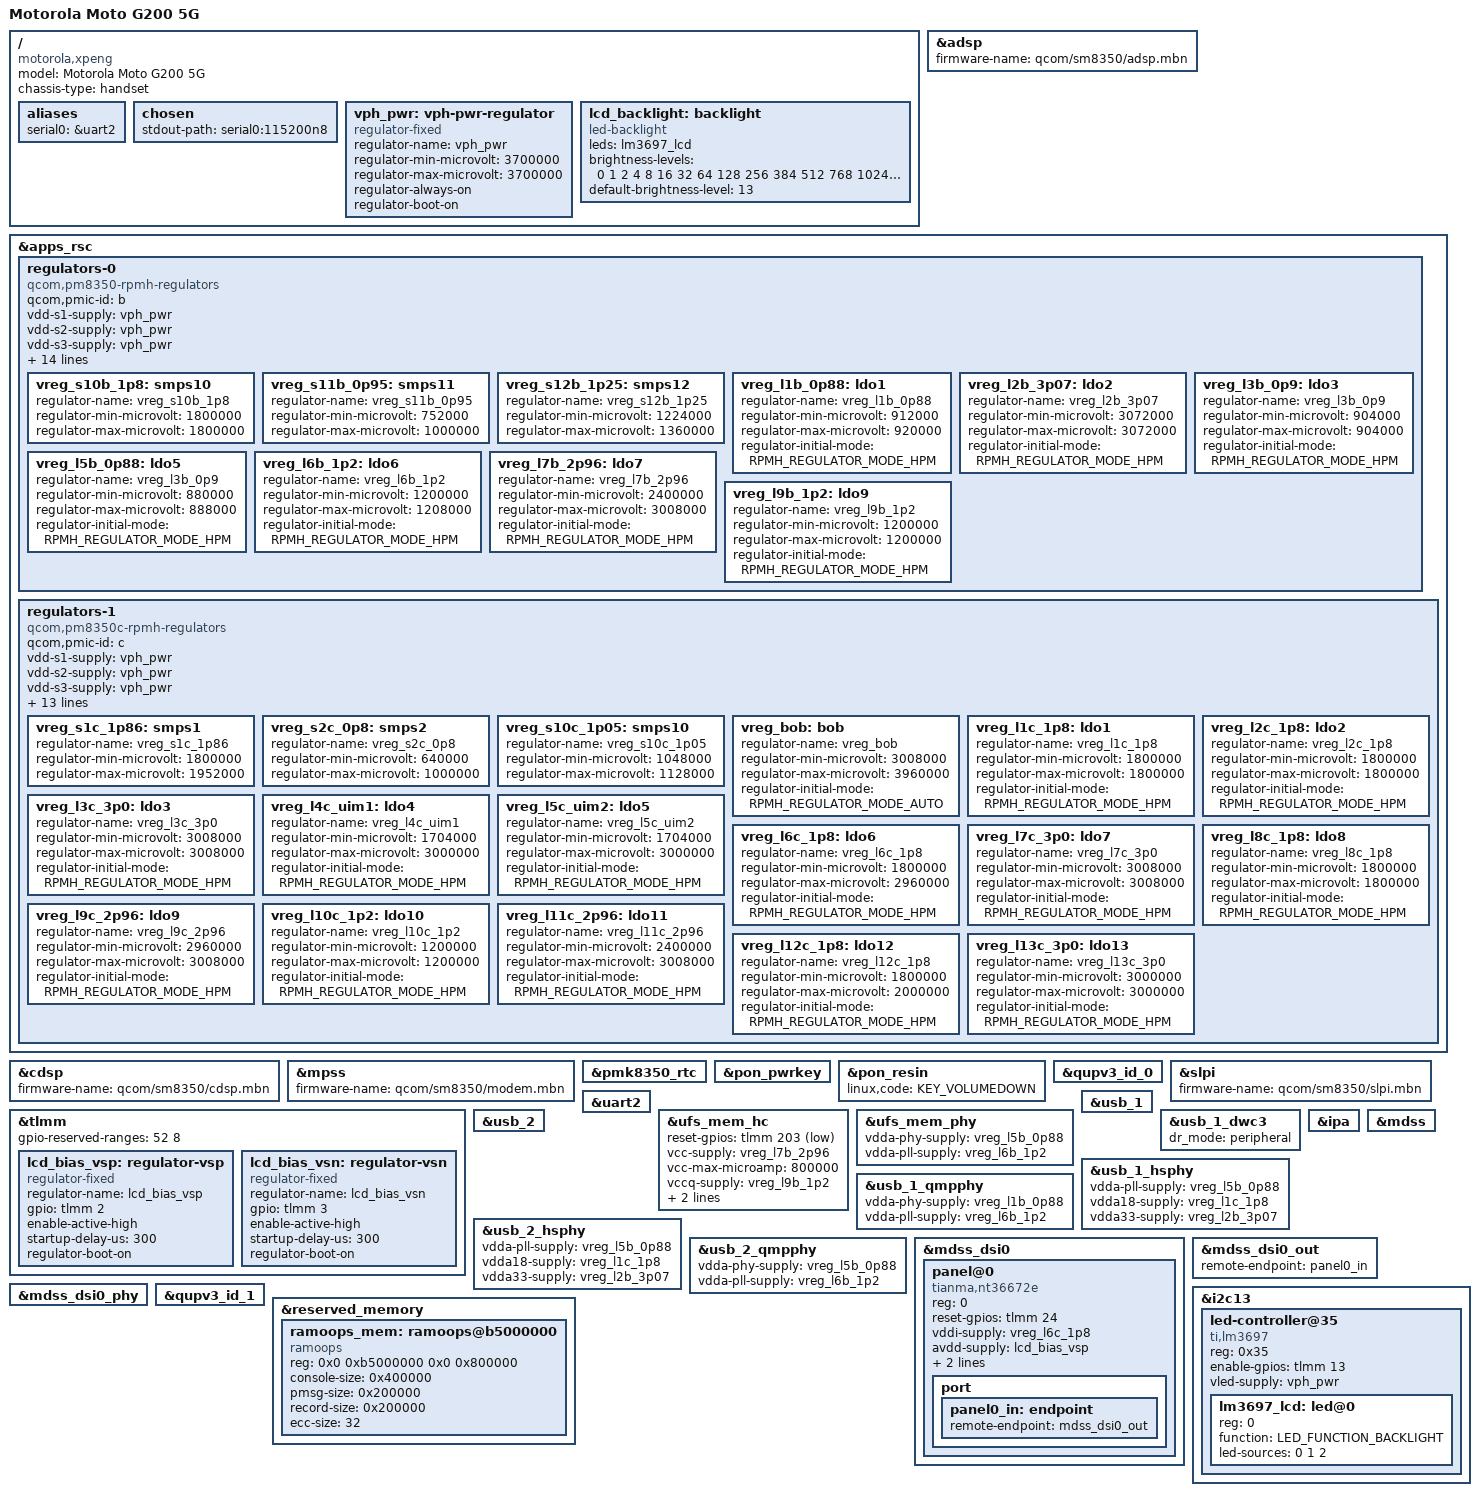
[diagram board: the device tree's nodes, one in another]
// SPDX-License-Identifier: BSD-3-Clause

/dts-v1/;

#include <dt-bindings/regulator/qcom,rpmh-regulator.h>
#include <dt-bindings/leds/common.h>
#include "sm8350.dtsi"
#include "pm8350.dtsi"
#include "pm8350b.dtsi"
#include "pm8350c.dtsi"
#include "pmk8350.dtsi"
#include "pmr735a.dtsi"
#include "pmr735b.dtsi"

/ {
	model = "Motorola Moto G200 5G";
	compatible = "motorola,xpeng", "qcom,sm8350";
	chassis-type = "handset";

	aliases {
		serial0 = &uart2;
	};

	chosen {
		stdout-path = "serial0:115200n8";
	};

	vph_pwr: vph-pwr-regulator {
		compatible = "regulator-fixed";
		regulator-name = "vph_pwr";
		regulator-min-microvolt = <3700000>;
		regulator-max-microvolt = <3700000>;

		regulator-always-on;
		regulator-boot-on;
	};
};

&adsp {
	status = "okay";
	firmware-name = "qcom/sm8350/adsp.mbn";
};

&apps_rsc {
	regulators-0 {
		compatible = "qcom,pm8350-rpmh-regulators";
		qcom,pmic-id = "b";

		vdd-s1-supply = <&vph_pwr>;
		vdd-s2-supply = <&vph_pwr>;
		vdd-s3-supply = <&vph_pwr>;
		vdd-s4-supply = <&vph_pwr>;
		vdd-s5-supply = <&vph_pwr>;
		vdd-s6-supply = <&vph_pwr>;
		vdd-s7-supply = <&vph_pwr>;
		vdd-s8-supply = <&vph_pwr>;
		vdd-s9-supply = <&vph_pwr>;
		vdd-s10-supply = <&vph_pwr>;
		vdd-s11-supply = <&vph_pwr>;
		vdd-s12-supply = <&vph_pwr>;

		vdd-l1-l4-supply = <&vreg_s11b_0p95>;
		vdd-l2-l7-supply = <&vreg_bob>;
		vdd-l3-l5-supply = <&vreg_bob>;
		vdd-l6-l9-l10-supply = <&vreg_s11b_0p95>;
		vdd-l8-supply = <&vreg_s2c_0p8>;

		vreg_s10b_1p8: smps10 {
			regulator-name = "vreg_s10b_1p8";
			regulator-min-microvolt = <1800000>;
			regulator-max-microvolt = <1800000>;
		};

		vreg_s11b_0p95: smps11 {
			regulator-name = "vreg_s11b_0p95";
			regulator-min-microvolt = <752000>;
			regulator-max-microvolt = <1000000>;
		};

		vreg_s12b_1p25: smps12 {
			regulator-name = "vreg_s12b_1p25";
			regulator-min-microvolt = <1224000>;
			regulator-max-microvolt = <1360000>;
		};

		vreg_l1b_0p88: ldo1 {
			regulator-name = "vreg_l1b_0p88";
			regulator-min-microvolt = <912000>;
			regulator-max-microvolt = <920000>;
			regulator-initial-mode = <RPMH_REGULATOR_MODE_HPM>;
		};

		vreg_l2b_3p07: ldo2 {
			regulator-name = "vreg_l2b_3p07";
			regulator-min-microvolt = <3072000>;
			regulator-max-microvolt = <3072000>;
			regulator-initial-mode = <RPMH_REGULATOR_MODE_HPM>;
		};

		vreg_l3b_0p9: ldo3 {
			regulator-name = "vreg_l3b_0p9";
			regulator-min-microvolt = <904000>;
			regulator-max-microvolt = <904000>;
			regulator-initial-mode = <RPMH_REGULATOR_MODE_HPM>;
		};

		vreg_l5b_0p88: ldo5 {
			regulator-name = "vreg_l3b_0p9";
			regulator-min-microvolt = <880000>;
			regulator-max-microvolt = <888000>;
			regulator-initial-mode = <RPMH_REGULATOR_MODE_HPM>;
		};

		vreg_l6b_1p2: ldo6 {
			regulator-name = "vreg_l6b_1p2";
			regulator-min-microvolt = <1200000>;
			regulator-max-microvolt = <1208000>;
			regulator-initial-mode = <RPMH_REGULATOR_MODE_HPM>;
		};

		vreg_l7b_2p96: ldo7 {
			regulator-name = "vreg_l7b_2p96";
			regulator-min-microvolt = <2400000>;
			regulator-max-microvolt = <3008000>;
			regulator-initial-mode = <RPMH_REGULATOR_MODE_HPM>;
		};

		vreg_l9b_1p2: ldo9 {
			regulator-name = "vreg_l9b_1p2";
			regulator-min-microvolt = <1200000>;
			regulator-max-microvolt = <1200000>;
			regulator-initial-mode = <RPMH_REGULATOR_MODE_HPM>;
		};
	};

	regulators-1 {
		compatible = "qcom,pm8350c-rpmh-regulators";
		qcom,pmic-id = "c";

		vdd-s1-supply = <&vph_pwr>;
		vdd-s2-supply = <&vph_pwr>;
		vdd-s3-supply = <&vph_pwr>;
		vdd-s4-supply = <&vph_pwr>;
		vdd-s5-supply = <&vph_pwr>;
		vdd-s6-supply = <&vph_pwr>;
		vdd-s7-supply = <&vph_pwr>;
		vdd-s8-supply = <&vph_pwr>;
		vdd-s9-supply = <&vph_pwr>;
		vdd-s10-supply = <&vph_pwr>;

		vdd-l1-l12-supply = <&vreg_s1c_1p86>;
		vdd-l2-l8-supply = <&vreg_s1c_1p86>;
		vdd-l3-l4-l5-l7-l13-supply = <&vreg_bob>;
		vdd-l6-l9-l11-supply = <&vreg_bob>;
		vdd-l10-supply = <&vreg_s12b_1p25>;

		vdd-bob-supply = <&vph_pwr>;

		vreg_s1c_1p86: smps1 {
			regulator-name = "vreg_s1c_1p86";
			regulator-min-microvolt = <1800000>;
			regulator-max-microvolt = <1952000>;
		};

		vreg_s2c_0p8: smps2 {
			regulator-name = "vreg_s2c_0p8";
			regulator-min-microvolt = <640000>;
			regulator-max-microvolt = <1000000>;
		};

		vreg_s10c_1p05: smps10 {
			regulator-name = "vreg_s10c_1p05";
			regulator-min-microvolt = <1048000>;
			regulator-max-microvolt = <1128000>;
		};

		vreg_bob: bob {
			regulator-name = "vreg_bob";
			regulator-min-microvolt = <3008000>;
			regulator-max-microvolt = <3960000>;
			regulator-initial-mode = <RPMH_REGULATOR_MODE_AUTO>;
		};

		vreg_l1c_1p8: ldo1 {
			regulator-name = "vreg_l1c_1p8";
			regulator-min-microvolt = <1800000>;
			regulator-max-microvolt = <1800000>;
			regulator-initial-mode = <RPMH_REGULATOR_MODE_HPM>;
		};

		vreg_l2c_1p8: ldo2 {
			regulator-name = "vreg_l2c_1p8";
			regulator-min-microvolt = <1800000>;
			regulator-max-microvolt = <1800000>;
			regulator-initial-mode = <RPMH_REGULATOR_MODE_HPM>;
		};

		vreg_l3c_3p0: ldo3 {
			regulator-name = "vreg_l3c_3p0";
			regulator-min-microvolt = <3008000>;
			regulator-max-microvolt = <3008000>;
			regulator-initial-mode = <RPMH_REGULATOR_MODE_HPM>;
		};

		vreg_l4c_uim1: ldo4 {
			regulator-name = "vreg_l4c_uim1";
			regulator-min-microvolt = <1704000>;
			regulator-max-microvolt = <3000000>;
			regulator-initial-mode = <RPMH_REGULATOR_MODE_HPM>;
		};

		vreg_l5c_uim2: ldo5 {
			regulator-name = "vreg_l5c_uim2";
			regulator-min-microvolt = <1704000>;
			regulator-max-microvolt = <3000000>;
			regulator-initial-mode = <RPMH_REGULATOR_MODE_HPM>;
		};

		vreg_l6c_1p8: ldo6 {
			regulator-name = "vreg_l6c_1p8";
			regulator-min-microvolt = <1800000>;
			regulator-max-microvolt = <2960000>;
			regulator-initial-mode = <RPMH_REGULATOR_MODE_HPM>;
		};

		vreg_l7c_3p0: ldo7 {
			regulator-name = "vreg_l7c_3p0";
			regulator-min-microvolt = <3008000>;
			regulator-max-microvolt = <3008000>;
			regulator-initial-mode = <RPMH_REGULATOR_MODE_HPM>;
		};

		vreg_l8c_1p8: ldo8 {
			regulator-name = "vreg_l8c_1p8";
			regulator-min-microvolt = <1800000>;
			regulator-max-microvolt = <1800000>;
			regulator-initial-mode = <RPMH_REGULATOR_MODE_HPM>;
		};

		vreg_l9c_2p96: ldo9 {
			regulator-name = "vreg_l9c_2p96";
			regulator-min-microvolt = <2960000>;
			regulator-max-microvolt = <3008000>;
			regulator-initial-mode = <RPMH_REGULATOR_MODE_HPM>;
		};

		vreg_l10c_1p2: ldo10 {
			regulator-name = "vreg_l10c_1p2";
			regulator-min-microvolt = <1200000>;
			regulator-max-microvolt = <1200000>;
			regulator-initial-mode = <RPMH_REGULATOR_MODE_HPM>;
		};

		vreg_l11c_2p96: ldo11 {
			regulator-name = "vreg_l11c_2p96";
			regulator-min-microvolt = <2400000>;
			regulator-max-microvolt = <3008000>;
			regulator-initial-mode = <RPMH_REGULATOR_MODE_HPM>;
		};

		vreg_l12c_1p8: ldo12 {
			regulator-name = "vreg_l12c_1p8";
			regulator-min-microvolt = <1800000>;
			regulator-max-microvolt = <2000000>;
			regulator-initial-mode = <RPMH_REGULATOR_MODE_HPM>;
		};

		vreg_l13c_3p0: ldo13 {
			regulator-name = "vreg_l13c_3p0";
			regulator-min-microvolt = <3000000>;
			regulator-max-microvolt = <3000000>;
			regulator-initial-mode = <RPMH_REGULATOR_MODE_HPM>;
		};
	};
};

&cdsp {
	status = "okay";
	firmware-name = "qcom/sm8350/cdsp.mbn";
};

&mpss {
	status = "okay";
	firmware-name = "qcom/sm8350/modem.mbn";
};

&pmk8350_rtc {
	status = "okay";
};

&pon_pwrkey {
	status = "okay";
};

&pon_resin {
	status = "okay";
	linux,code = <KEY_VOLUMEDOWN>;
};

&qupv3_id_0 {
	status = "okay";
};

&slpi {
	status = "okay";
	firmware-name = "qcom/sm8350/slpi.mbn";
};

&tlmm {
	gpio-reserved-ranges = <52 8>;

	lcd_bias_vsp: regulator-vsp {
		compatible = "regulator-fixed";
		regulator-name = "lcd_bias_vsp";
		gpio = <&tlmm 2 GPIO_ACTIVE_HIGH>;
		enable-active-high;
		startup-delay-us = <300>;
		regulator-boot-on;
	};

	lcd_bias_vsn: regulator-vsn {
		compatible = "regulator-fixed";
		regulator-name = "lcd_bias_vsn";
		gpio = <&tlmm 3 GPIO_ACTIVE_HIGH>;
		enable-active-high;
		startup-delay-us = <300>;
		regulator-boot-on;
	};
};

&uart2 {
	status = "okay";
};

&ufs_mem_hc {
	status = "okay";

	reset-gpios = <&tlmm 203 GPIO_ACTIVE_LOW>;

	vcc-supply = <&vreg_l7b_2p96>;
	vcc-max-microamp = <800000>;
	vccq-supply = <&vreg_l9b_1p2>;
	vccq-max-microamp = <900000>;
	vdd-hba-supply = <&vreg_l9b_1p2>;
};

&ufs_mem_phy {
	status = "okay";

	vdda-phy-supply = <&vreg_l5b_0p88>;
	vdda-pll-supply = <&vreg_l6b_1p2>;
};

&usb_1 {
	status = "okay";
};

&usb_1_dwc3 {
	dr_mode = "peripheral";
};

&usb_1_hsphy {
	status = "okay";

	vdda-pll-supply = <&vreg_l5b_0p88>;
	vdda18-supply = <&vreg_l1c_1p8>;
	vdda33-supply = <&vreg_l2b_3p07>;
};

&usb_1_qmpphy {
	status = "okay";

	vdda-phy-supply = <&vreg_l1b_0p88>;
	vdda-pll-supply = <&vreg_l6b_1p2>;
};

&usb_2 {
	status = "okay";
};

&usb_2_hsphy {
	status = "okay";

	vdda-pll-supply = <&vreg_l5b_0p88>;
	vdda18-supply = <&vreg_l1c_1p8>;
	vdda33-supply = <&vreg_l2b_3p07>;
};

&usb_2_qmpphy {
	status = "okay";

	vdda-phy-supply = <&vreg_l5b_0p88>;
	vdda-pll-supply = <&vreg_l6b_1p2>;
};

&ipa {
	status = "okay";
};

&mdss {
	status = "okay";
};

&mdss_dsi0 {
	status = "okay";

	panel@0 {
		compatible = "tianma,nt36672e";
		reg = <0>;

		reset-gpios = <&tlmm 24 GPIO_ACTIVE_HIGH>;

		vddi-supply = <&vreg_l6c_1p8>;
		avdd-supply = <&lcd_bias_vsp>;
		avee-supply = <&lcd_bias_vsn>;

		backlight = <&lcd_backlight>;

		port {
			panel0_in: endpoint {
				remote-endpoint = <&mdss_dsi0_out>;
			};
		};
	};
};

&mdss_dsi0_out {
	remote-endpoint = <&panel0_in>;
};

&mdss_dsi0_phy {
	status = "okay";
};

&qupv3_id_1 {
	status = "okay";
};

&i2c13 {
	status = "okay";

	led-controller@35 {
		compatible = "ti,lm3697";
		reg = <0x35>;
		#address-cells = <1>;
		#size-cells = <0>;

		enable-gpios = <&tlmm 13 GPIO_ACTIVE_HIGH>;
		vled-supply = <&vph_pwr>;

		lm3697_lcd: led@0 {
			reg = <0>;
			function = LED_FUNCTION_BACKLIGHT;
			led-sources = <0 1 2>;
		};
	};
};

/ {
	lcd_backlight: backlight {
		compatible = "led-backlight";
		leds = <&lm3697_lcd>;
		brightness-levels = <0 1 2 4 8 16 32 64 128 256 384 512 768 1024 1536 2047>;
		default-brightness-level = <13>;
	};
};

&reserved_memory {
	ramoops_mem: ramoops@b5000000 {
		compatible = "ramoops";
		reg = <0x0 0xb5000000 0x0 0x800000>;
		console-size = <0x400000>;
		pmsg-size = <0x200000>;
		record-size = <0x200000>;
		ecc-size = <32>;
	};
};
